# MKE16Z4 register map
Vendor: nxp.com; File version: 1.0
CPU: CM0PLUS r0p0, little endian, no MPU, no FPU, VTOR, 2 interrupt priority bits
Registers are 32-bit, read-write, reset 0x0 unless marked. A register's access mark holds for its fields unless they carry their own. Offsets are from the block's base; [hi:lo] are bit positions.

## RTC — Secure Real Time Clock
Base 0x4003D000; register names take the prefix RTC_
0x00 TSR — RTC Time Seconds Register
  [31:0] TSR — Time Seconds Register
0x04 TPR — RTC Time Prescaler Register
  [15:0] TPR — Time Prescaler Register
0x08 TAR — RTC Time Alarm Register
  [31:0] TAR — Time Alarm Register
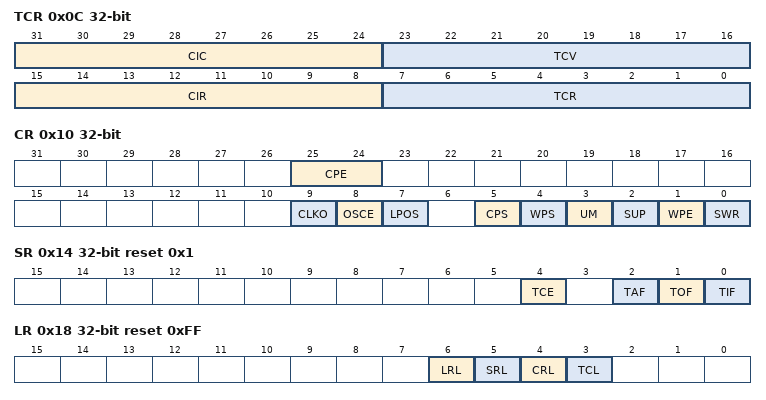
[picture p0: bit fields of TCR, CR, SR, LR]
0x0C TCR — RTC Time Compensation Register
  [31:24] CIC ro — Compensation Interval Counter
  [23:16] TCV ro — Time Compensation Value
  [15:8] CIR — Compensation Interval Register
  [7:0] TCR — Time Compensation Register
    0=Time Prescaler Register overflows every 32768 clock cycles; 1=Time Prescaler Register overflows every 32767 clock cycles; 127=Time Prescaler Register overflows every 32641 clock cycles; 128=Time Prescaler Register overflows every 32896 clock cycles; 255=Time Prescaler Register overflows every 32769 clock cycles
0x10 CR — RTC Control Register
  [25:24] CPE — Clock Pin Enable
    0=DISABLED (RTC_CLKOUT is disabled.); 1=RTC_PTE0 (RTC_CLKOUT is enabled.)
  [9] CLKO — Clock Output
    0=ENABLED (The 32 kHz clock is allowed to output on RTC_CLKOUT.); 1=DISABLED (The 32 kHz clock is not allowed to output on RTC_CLKOUT.)
  [8] OSCE — Oscillator Enable
    0=DISABLED (32.768 kHz oscillator is disabled.); 1=ENABLED (32.768 kHz oscillator is enabled. After setting this bit, wait the oscillator startup time before enabling the time counter to allow the 32.768 kHz clock time to stabilize.)
  [7] LPOS — LPO Select
    0=CRYSTAL (RTC prescaler increments using 32 kHz clock.); 1=LPO (RTC prescaler increments using LPO, bits [4:0] of the prescaler are bypassed.)
  [5] CPS — Clock Pin Select
    0=PRESCALER (The prescaler output clock (as configured by TSIC) is output on RTC_CLKOUT.); 1=CRYSTAL (The RTC 32kHz clock is output on RTC_CLKOUT.)
  [4] WPS — Wakeup Pin Select
    0=ASSERTED (Wakeup pin asserts (active low, open drain) if the RTC interrupt asserts or the wakeup pin is turned on.); 1=RTC_32KHZ (Wakeup pin instead outputs the RTC 32kHz clock, provided the wakeup pin is turned on and the 32kHz clock is output to other peripherals.)
  [3] UM — Update Mode
    0=PROTECTED (Registers cannot be written when locked.); 1=WRITEABLE (Registers can be written when locked under limited conditions.)
  [2] SUP — Supervisor Access
    0=NON_SUPPORTED (Non-supervisor mode write accesses are not supported and generate a bus error.); 1=SUPPORTED (Non-supervisor mode write accesses are supported.)
  [1] WPE — Wakeup Pin Enable
    0=DISABLED (Wakeup pin is disabled.); 1=ENABLED (Wakeup pin is enabled and wakeup pin asserts if the RTC interrupt asserts or the wakeup pin is turned on.)
  [0] SWR — Software Reset
    0=NO_EFFECT; 1=RESET (Resets all RTC registers except for the SWR bit and the RTC_WAR and RTC_RAR registers . The SWR bit is cleared by POR and by software explicitly clearing it.)
0x14 SR reset 0x1 — RTC Status Register
  [4] TCE — Time Counter Enable
    0=DISABLED (Time counter is disabled.); 1=ENABLED (Time counter is enabled.)
  [2] TAF ro — Time Alarm Flag
    0=NOT_OCCURED (Time alarm has not occurred.); 1=OCCURED (Time alarm has occurred.)
  [1] TOF ro — Time Overflow Flag
    0=NOT_OCCURED (Time overflow has not occurred.); 1=OCCURED (Time overflow has occurred and time counter is read as zero.)
  [0] TIF ro — Time Invalid Flag
    0=VALID (Time is valid.); 1=INVALID (Time is invalid and time counter is read as zero.)
0x18 LR reset 0xFF — RTC Lock Register
  [6] LRL — Lock Register Lock
    0=LOCKED (Lock Register is locked and writes are ignored.); 1=NORMAL (Lock Register is not locked and writes complete as normal.)
  [5] SRL — Status Register Lock
    0=LOCKED (Status Register is locked and writes are ignored.); 1=NORMAL (Status Register is not locked and writes complete as normal.)
  [4] CRL — Control Register Lock
    0=LOCKED (Control Register is locked and writes are ignored.); 1=NORMAL (Control Register is not locked and writes complete as normal.)
  [3] TCL — Time Compensation Lock
    0=LOCKED (Time Compensation Register is locked and writes are ignored.); 1=NORMAL (Time Compensation Register is not locked and writes complete as normal.)
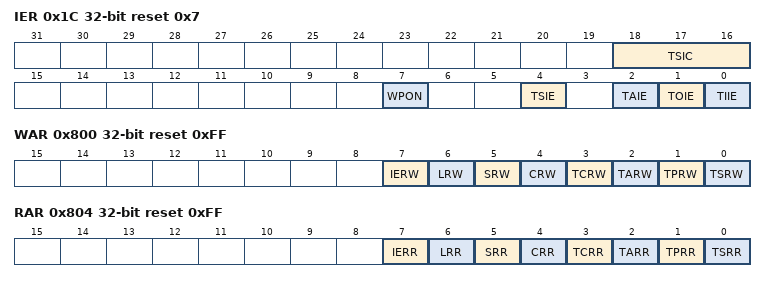
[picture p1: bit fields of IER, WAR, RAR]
0x1C IER reset 0x7 — RTC Interrupt Enable Register
  [18:16] TSIC — Timer Seconds Interrupt Configuration
    0=F1HZ (1 Hz.); 1=F2HZ (2 Hz.); 2=F4HZ (4 Hz.); 3=F8HZ (8 Hz.); 4=F16HZ (16 Hz.); 5=F32HZ (32 Hz.); 6=F64HZ (64 Hz.); 7=F128HZ (128 Hz.)
  [7] WPON — Wakeup Pin On
    0=NO_EFFECT; 1=ON (If the wakeup pin is enabled, then the wakeup pin will assert.)
  [4] TSIE — Time Seconds Interrupt Enable
    0=DISABLED (Seconds interrupt is disabled.); 1=ENABLED (Seconds interrupt is enabled.)
  [2] TAIE — Time Alarm Interrupt Enable
    0=DISABLED (Time alarm flag does not generate an interrupt.); 1=ENABLED (Time alarm flag does generate an interrupt.)
  [1] TOIE — Time Overflow Interrupt Enable
    0=DISABLED (Time overflow flag does not generate an interrupt.); 1=ENABLED (Time overflow flag does generate an interrupt.)
  [0] TIIE — Time Invalid Interrupt Enable
    0=DISABLED (Time invalid flag does not generate an interrupt.); 1=ENABLED (Time invalid flag does generate an interrupt.)
0x800 WAR reset 0xFF — RTC Write Access Register
  [7] IERW — Interrupt Enable Register Write
    0=IGNORED (Writes to the Interupt Enable Register are ignored.); 1=NORMAL (Writes to the Interrupt Enable Register complete as normal.)
  [6] LRW — Lock Register Write
    0=IGNORED (Writes to the Lock Register are ignored.); 1=NORMAL (Writes to the Lock Register complete as normal.)
  [5] SRW — Status Register Write
    0=IGNORED (Writes to the Status Register are ignored.); 1=NORMAL (Writes to the Status Register complete as normal.)
  [4] CRW — Control Register Write
    0=IGNORED (Writes to the Control Register are ignored.); 1=NORMAL (Writes to the Control Register complete as normal.)
  [3] TCRW — Time Compensation Register Write
    0=IGNORED (Writes to the Time Compensation Register are ignored.); 1=NORMAL (Writes to the Time Compensation Register complete as normal.)
  [2] TARW — Time Alarm Register Write
    0=IGNORED (Writes to the Time Alarm Register are ignored.); 1=NORMAL (Writes to the Time Alarm Register complete as normal.)
  [1] TPRW — Time Prescaler Register Write
    0=IGNORED (Writes to the Time Prescaler Register are ignored.); 1=NORMAL (Writes to the Time Prescaler Register complete as normal.)
  [0] TSRW — Time Seconds Register Write
    0=IGNORED (Writes to the Time Seconds Register are ignored.); 1=NORMAL (Writes to the Time Seconds Register complete as normal.)
0x804 RAR reset 0xFF — RTC Read Access Register
  [7] IERR — Interrupt Enable Register Read
    0=IGNORED (Reads to the Interrupt Enable Register are ignored.); 1=NORMAL (Reads to the Interrupt Enable Register complete as normal.)
  [6] LRR — Lock Register Read
    0=IGNORED (Reads to the Lock Register are ignored.); 1=NORMAL (Reads to the Lock Register complete as normal.)
  [5] SRR — Status Register Read
    0=IGNORED (Reads to the Status Register are ignored.); 1=NORMAL (Reads to the Status Register complete as normal.)
  [4] CRR — Control Register Read
    0=IGNORED (Reads to the Control Register are ignored.); 1=NORMAL (Reads to the Control Register complete as normal.)
  [3] TCRR — Time Compensation Register Read
    0=IGNORED (Reads to the Time Compensation Register are ignored.); 1=NORMAL (Reads to the Time Compensation Register complete as normal.)
  [2] TARR — Time Alarm Register Read
    0=IGNORED (Reads to the Time Alarm Register are ignored.); 1=NORMAL (Reads to the Time Alarm Register complete as normal.)
  [1] TPRR — Time Prescaler Register Read
    0=IGNORED (Reads to the Time Pprescaler Register are ignored.); 1=NORMAL (Reads to the Time Prescaler Register complete as normal.)
  [0] TSRR — Time Seconds Register Read
    0=IGNORED (Reads to the Time Seconds Register are ignored.); 1=NORMAL (Reads to the Time Seconds Register complete as normal.)
